# MKE15D7 register map
File version: 1.6
Registers are 32-bit, read-write, reset 0x0 unless marked. A register's access mark holds for its fields unless they carry their own. Offsets are from the block's base; [hi:lo] are bit positions; {n}, {i} and the like mark numbered series; 'fields as' and 'values as' point back to an identical list.

## TSI0 — Touch Sensing Input
Base 0x40030000; register names take the prefix TSI0_
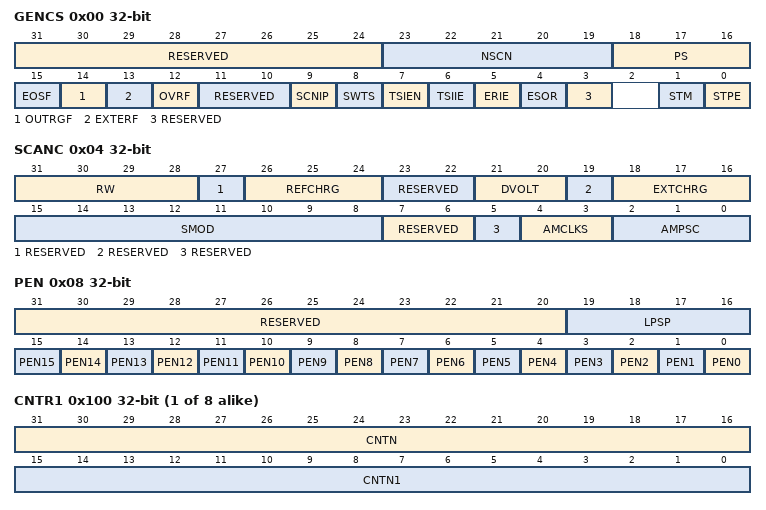
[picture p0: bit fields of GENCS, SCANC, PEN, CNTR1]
0x00 GENCS — General Control and Status Register
  [31:24] RESERVED ro
  [23:19] NSCN — Number of Consecutive Scans per Electrode electrode.
    0=Once per electrode; 1=Twice per electrode; {v}={v+1} times per electrode (v=2..31)
  [18:16] PS — Electrode Oscillator prescaler. .
    0=Electrode Oscillator Frequency divided by 1; 1=Electrode Oscillator Frequency divided by 2; 2=Electrode Oscillator Frequency divided by 4; 3=Electrode Oscillator Frequency divided by 8; 4=Electrode Oscillator Frequency divided by 16; 5=Electrode Oscillator Frequency divided by 32; 6=Electrode Oscillator Frequency divided by 64; 7=Electrode Oscillator Frequency divided by 128
  [15] EOSF — End of Scan Flag.
  [14] OUTRGF — Out of Range Flag.
  [13] EXTERF — External Electrode error occurred
    0=No short; 1=Short to VDD or VSS was detected on one or more electrodes
  [12] OVRF — Overrun error Flag. This flag is set when a scan trigger occurs while a scan is still in progress. Write "1", when this flag is set, to clear it..
    0=No over run; 1=Over Run occurred
  [11:10] RESERVED ro
  [9] SCNIP ro — Scan In Progress status
  [8] SWTS wo — Software Trigger Start
  [7] TSIEN — Touch Sensing Input Module Enable
    0=Disable; 1=Enable
  [6] TSIIE — Touch Sensing Input Interrupt Module Enable
    0=Interrupt from TSI is disabled; 1=Interrupt from TSI is enabled
  [5] ERIE — Error Interrupt Enable
    0=Interrupt disabled for error; 1=Interrupt enabled for error
  [4] ESOR — End-of-Scan or Out-of-Range Interrupt select
    0=Out-of-Range interrupt is allowed; 1=End-of-Scan interrupt is allowed
  [3] RESERVED ro
  [1] STM — Scan Trigger Mode. User is allowed to change this bit when TSI is not working in progress.
    0=Software trigger scan; 1=Periodical Scan
  [0] STPE
    0=Disable TSI when MCU goes into low power modes; 1=Allows TSI to continue running in all low power modes
0x04 SCANC — SCAN Control Register
  [31:28] RW
    0=Normal operation
  [27] RESERVED ro
  [26:24] REFCHRG — Ref OSC Charge Current select
    0=0.5 uA charge current; 1=1 uA charge current; 2=2 uA charge current; 3=4 uA charge current; 4=8 uA charge current; 5=16 uA charge current; 6=32 uA charge current; 7=64 uA charge current
  [23:22] RESERVED ro
  [21:20] DVOLT
    0=Vp = 1.33 V, Vm = 0.30 V, DV = 1.03 V; 1=Vp = 1.18 V, Vm = 0.45 V, DV = 0.73 V; 2=Vp = 1.03 V, Vm = 0.60 V, DV = 0.43 V; 3=Vp = 0.95 V, Vm = 0.67 V, DV = 0.29 V
  [19] RESERVED ro
  [18:16] EXTCHRG — External OSC Charge Current select
    values as REFCHRG
  [15:8] SMOD — Scan Module
    0=Continuous Scan
  [7:6] RESERVED ro
  [5] RESERVED ro
  [4:3] AMCLKS — Active Mode Clock Source
    0=LPOCLK; 1=IRCLK; 2=ERCLK; 3=Not valid
  [2:0] AMPSC — Active Mode Prescaler
    0=Input Clock Source divided by 1; 1=Input Clock Source divided by 2; 2=Input Clock Source divided by 4; 3=Input Clock Source divided by 8; 4=Input Clock Source divided by 16; 5=Input Clock Source divided by 32; 6=Input Clock Source divided by 64; 7=Input Clock Source divided by 128
0x08 PEN — Pin Enable Register
  [31:20] RESERVED ro
  [19:16] LPSP — Low Power Scan Pin
    {v}=TSI_IN[{v}] is active in low power mode (v=0..15)
  [n] PEN{n} (n=0..15) — Touch Sensing Input Pin Enable Register {n}
    0=The corresponding pin is not used by TSI; 1=The corresponding pin is used by TSI
0x100 CNTR{x} (x=1,3,5,7,9,11,13,15; step 0x4) ro — Counter Register
  [31:16] CNTN — TouchSensing Channel n 16-bit counter value
  [15:0] CNTN1 — TouchSensing Channel n-1 16-bit counter value
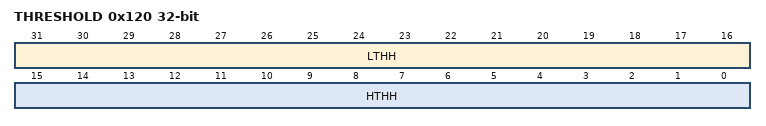
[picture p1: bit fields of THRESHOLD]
0x120 THRESHOLD — Low Power Channel Threshold Register
  [31:16] LTHH — Touch Sensing Channel Low Threshold value
  [15:0] HTHH — Touch Sensing Channel High Threshold value
